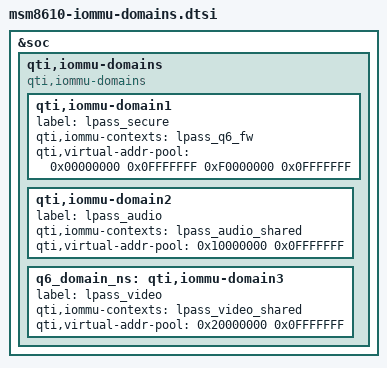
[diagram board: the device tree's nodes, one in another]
/* Copyright (c) 2012-2013, The Linux Foundation. All rights reserved.
 *
 * This program is free software; you can redistribute it and/or modify
 * it under the terms of the GNU General Public License version 2 and
 * only version 2 as published by the Free Software Foundation.
 *
 * This program is distributed in the hope that it will be useful,
 * but WITHOUT ANY WARRANTY; without even the implied warranty of
 * MERCHANTABILITY or FITNESS FOR A PARTICULAR PURPOSE.  See the
 * GNU General Public License for more details.
 */

&soc {
	qti,iommu-domains {
		compatible = "qti,iommu-domains";

		qti,iommu-domain1 {
			label = "lpass_secure";
			qti,iommu-contexts = <&lpass_q6_fw>;
			qti,virtual-addr-pool = <0x00000000 0x0FFFFFFF
						  0xF0000000 0x0FFFFFFF>;
		};

		qti,iommu-domain2 {
			label = "lpass_audio";
			qti,iommu-contexts = <&lpass_audio_shared>;
			qti,virtual-addr-pool = <0x10000000 0x0FFFFFFF>;
		};

		q6_domain_ns:qti,iommu-domain3 {
			label = "lpass_video";
			qti,iommu-contexts = <&lpass_video_shared>;
			qti,virtual-addr-pool = <0x20000000 0x0FFFFFFF>;
		};
	};
};
